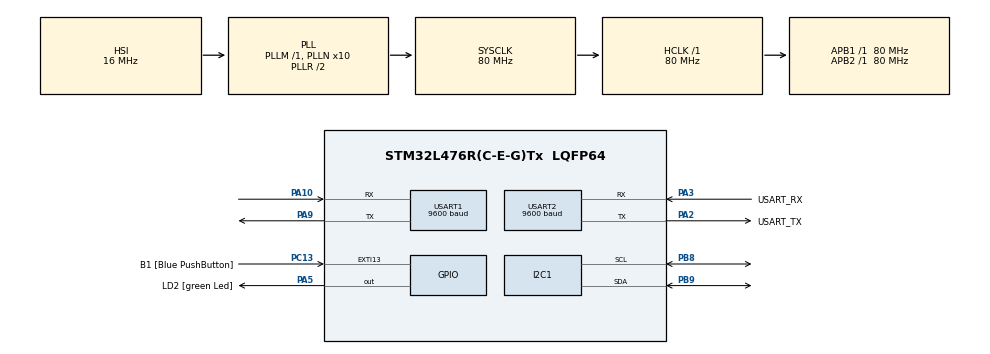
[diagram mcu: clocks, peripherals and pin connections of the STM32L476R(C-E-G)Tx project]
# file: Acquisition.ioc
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I2C1.Timing=0x10D19CE4
Mcu.Family=STM32L4
Mcu.Name=STM32L476R(C-E-G)Tx
Mcu.Package=LQFP64
NVIC.PriorityGroup=NVIC_PRIORITYGROUP_4
PA10.Mode=Asynchronous
PA10.Signal=USART1_RX
PA13\ (JTMS-SWDIO).GPIO_Label=TMS
PA13\ (JTMS-SWDIO).Mode=Serial_Wire
PA13\ (JTMS-SWDIO).Signal=SYS_JTMS-SWDIO
PA14\ (JTCK-SWCLK).GPIO_Label=TCK
PA14\ (JTCK-SWCLK).Mode=Serial_Wire
PA14\ (JTCK-SWCLK).Signal=SYS_JTCK-SWCLK
PA2.GPIO_Label=USART_TX
PA2.GPIO_Mode=GPIO_MODE_AF_PP
PA2.GPIO_PuPd=GPIO_NOPULL
PA2.GPIO_Speed=GPIO_SPEED_FREQ_VERY_HIGH
PA2.Mode=Asynchronous
PA2.Signal=USART2_TX
PA3.GPIO_Label=USART_RX
PA3.GPIO_Mode=GPIO_MODE_AF_PP
PA3.GPIO_PuPd=GPIO_NOPULL
PA3.GPIO_Speed=GPIO_SPEED_FREQ_VERY_HIGH
PA3.Mode=Asynchronous
PA3.Signal=USART2_RX
PA5.GPIO_Label=LD2 [green Led]
PA5.GPIO_ModeDefaultOutputPP=GPIO_MODE_OUTPUT_PP
PA5.GPIO_PuPd=GPIO_NOPULL
PA5.GPIO_Speed=GPIO_SPEED_FREQ_LOW
PA5.Signal=GPIO_Output
PA9.Mode=Asynchronous
PA9.Signal=USART1_TX
PB3\ (JTDO-TRACESWO).GPIO_Label=SWO
PB3\ (JTDO-TRACESWO).Signal=SYS_JTDO-SWO
PB8.Mode=I2C
PB8.Signal=I2C1_SCL
PB9.Mode=I2C
PB9.Signal=I2C1_SDA
PC13.GPIO_Label=B1 [Blue PushButton]
PC13.GPIO_ModeDefaultEXTI=GPIO_MODE_IT_FALLING
PC13.GPIO_PuPd=GPIO_NOPULL
PC13.Signal=GPXTI13
PC14-OSC32_IN\ (PC14).Mode=LSE-External-Oscillator
PC14-OSC32_IN\ (PC14).Signal=RCC_OSC32_IN
PC15-OSC32_OUT\ (PC15).Mode=LSE-External-Oscillator
PC15-OSC32_OUT\ (PC15).Signal=RCC_OSC32_OUT
PH0-OSC_IN\ (PH0).Signal=RCC_OSC_IN
PH1-OSC_OUT\ (PH1).Signal=RCC_OSC_OUT
ProjectManager.HeapSize=0x200
ProjectManager.StackSize=0x400
ProjectManager.TargetToolchain=STM32CubeIDE
RCC.ADCFreq_Value=64000000
RCC.AHBFreq_Value=80000000
RCC.APB1Freq_Value=80000000
RCC.APB1TimFreq_Value=80000000
RCC.APB2Freq_Value=80000000
RCC.APB2TimFreq_Value=80000000
RCC.CortexFreq_Value=80000000
RCC.HCLKFreq_Value=80000000
RCC.HSE_VALUE=8000000
RCC.HSI_VALUE=16000000
RCC.MSI_VALUE=4000000
RCC.PLLN=10
RCC.PLLSourceVirtual=RCC_PLLSOURCE_HSI
RCC.PREFETCH_ENABLE=1
RCC.SYSCLKFreq_VALUE=80000000
RCC.SYSCLKSource=RCC_SYSCLKSOURCE_PLLCLK
RCC.USBFreq_Value=64000000
RCC.VCOOutputFreq_Value=160000000
USART1.BaudRate=9600
USART1.VirtualMode-Asynchronous=VM_ASYNC
USART2.BaudRate=9600
USART2.VirtualMode-Asynchronous=VM_ASYNC
board=NUCLEO-L476RG

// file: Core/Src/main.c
/* USER CODE BEGIN Header */
/**
  ******************************************************************************
  * @file           : main.c
  * @brief          : Main program body
  ******************************************************************************
  * @attention
  *
  * Copyright (c) 2025 STMicroelectronics.
  * All rights reserved.
  *
  * This software is licensed under terms that can be found in the LICENSE file
  * in the root directory of this software component.
  * If no LICENSE file comes with this software, it is provided AS-IS.
  *
  ******************************************************************************
  */
/* USER CODE END Header */

#include "main.h"
#include "i2c.h"
#include "usart.h"
#include "gpio.h"
#include "lcd.h"
#include <string.h>
#include <stdio.h>
#include <stdlib.h>

/* USER CODE BEGIN PV */
// LCD variable
rgb_lcd lcd;

int weightMg;
float weightG;

// LoRa command and response buffers
char loraCmd[64];
char loraResp[256];
char loraMsg[64];
char loraRetMsg[256];

/* USER CODE END PV */

void SystemClock_Config(void);
void displayData(char *message);
void initializePeripherals(void);
void sendLoRaCommand(const char* cmd);
void clearBuffers(void);

/* USER CODE BEGIN PFP */
#define PUTCHAR_PROTOTYPE int __io_putchar(int ch)
/* USER CODE END PFP */

int main(void)
{

  /* MCU Configuration--------------------------------------------------------*/

  /* Reset of all peripherals, Initializes the Flash interface and the Systick. */
  HAL_Init();

  /* Configure the system clock */
  SystemClock_Config();

  /* Initialize all configured peripherals */
  initializePeripherals();

  // Send initial LoRa commands
  sendLoRaCommand("AT\r\n");
  sendLoRaCommand("AT+MODE=TEST\r\n");

  // Set LoRa module to receive mode
  sendLoRaCommand("AT+TEST=RXLRPKT\r\n");

  /* Infinite loop */
  while (1)
  {

    // Wait and retrieve the message
    HAL_UART_Receive(&huart1, (uint8_t*)loraRetMsg, sizeof(loraRetMsg), 1000);
    HAL_UART_Transmit(&huart2, (uint8_t*)loraRetMsg, strlen(loraRetMsg), 1000);

    // Check if the received message contains "+TEST: RX "
    char *start = strstr(loraRetMsg, "+TEST: RX \"");
    if (start != NULL)
    {
        start += 11; // Move past "+TEST: RX \""
        displayData(start);
    }

    // Clear buffers to avoid stale data
    clearBuffers();

  }
}

/**
  * @brief Initialize peripherals and LCD.
  */
void initializePeripherals(void)
{
  MX_GPIO_Init();
  MX_USART2_UART_Init();
  MX_USART1_UART_Init();
  MX_I2C1_Init();

  lcd_init(&hi2c1, &lcd);
  clearlcd();
}

/**
  * @brief Send a command to the LoRa module.
  */
void sendLoRaCommand(const char* cmd)
{
  snprintf(loraCmd, sizeof(loraCmd), "%s", cmd);
  HAL_UART_Transmit(&huart1, (uint8_t*)loraCmd, strlen(loraCmd), 1000);
  HAL_UART_Receive(&huart1, (uint8_t*)loraResp, sizeof(loraResp), 1000);
}

/**
  * @brief Clear the command and response buffers.
  */
void clearBuffers(void)
{
  memset(loraMsg, 0, sizeof(loraMsg));
  memset(loraRetMsg, 0, sizeof(loraRetMsg));
}

/**
  * @brief Display data on the LCD based on the message ID.
  */
void displayData(char *message) {
    char buff[20];

    // Check if the message is from the external temperature and humidity sensor (ID "01")
    if (strncmp(message, "01", 2) == 0) {
        clearlcd();
        lcd_position(&hi2c1, 0, 0);
        lcd_print(&hi2c1, "Temp & Humidity");
        lcd_position(&hi2c1, 0, 1);
        lcd_print(&hi2c1, "Outside");
        HAL_Delay(2000);
        clearlcd();

        // Extract and display temperature
        snprintf(buff, sizeof(buff), "Temp: %c%c.%c%c C", message[2], message[3], message[4], message[5]);
        lcd_position(&hi2c1, 0, 0);
        lcd_print(&hi2c1, buff);
        memset(buff, 0, sizeof(buff));

        // Extract and display humidity
        snprintf(buff, sizeof(buff), "Hum: %c%c.%c%c %%", message[6], message[7], message[8], message[9]);
        lcd_position(&hi2c1, 0, 1);
        lcd_print(&hi2c1, buff);
        memset(buff, 0, sizeof(buff));
    }

    // Check if the message is from the weight sensor (ID "02")
    else if (strncmp(message, "02", 2) == 0) {
        weightMg = atoi(&message[2]); // Convert string to integer (mg)
        weightG = weightMg / 1000.0; // Convert to grams

        clearlcd();
        lcd_position(&hi2c1, 2, 0);
        lcd_print(&hi2c1, "Current Weight");
        lcd_position(&hi2c1, 2, 1);
        lcd_print(&hi2c1, "in Hive");
        HAL_Delay(2000);
        clearlcd();

        lcd_position(&hi2c1, 0, 0);
        lcd_print(&hi2c1, "Hive Weight:");
        snprintf(buff, sizeof(buff), "%.2f g", weightG);
        lcd_position(&hi2c1, 0, 1);
        lcd_print(&hi2c1, buff);
        memset(buff, 0, sizeof(buff));
    }

    // Check for an alternative format of the weight sensor (ID "002")
    else if (strncmp(message, "002", 3) == 0) {
        weightMg = atoi(&message[3]);
        weightG = weightMg / 1000.0;

        clearlcd();
        lcd_position(&hi2c1, 2, 0);
        lcd_print(&hi2c1, "Current Weight");
        lcd_position(&hi2c1, 2, 1);
        lcd_print(&hi2c1, "in Hive");
        HAL_Delay(2000);
        clearlcd();

        lcd_position(&hi2c1, 0, 0);
        lcd_print(&hi2c1, "Hive Weight:");
        snprintf(buff, sizeof(buff), "%.2f g", weightG);
        lcd_position(&hi2c1, 0, 1);
        lcd_print(&hi2c1, buff);
        memset(buff, 0, sizeof(buff));
    }

    // Check if the message is from the internal temperature and humidity sensor (ID "03")
    else if (strncmp(message, "03", 2) == 0) {
        clearlcd();
        lcd_position(&hi2c1, 0, 0);
        lcd_print(&hi2c1, "Temp & Humidity");
        lcd_position(&hi2c1, 0, 1);
        lcd_print(&hi2c1, "Inside");
        HAL_Delay(2000);
        clearlcd();

        // Extract and display temperature
        snprintf(buff, sizeof(buff), "Temp: %c%c.%c C", message[2], message[3], message[4]);
        lcd_position(&hi2c1, 0, 0);
        lcd_print(&hi2c1, buff);
        memset(buff, 0, sizeof(buff));

        // Extract and display humidity
        snprintf(buff, sizeof(buff), "Hum: %c%c.%c %%", message[5], message[6], message[7]);
        lcd_position(&hi2c1, 0, 1);
        lcd_print(&hi2c1, buff);
        memset(buff, 0, sizeof(buff));
    }

    // Check if motion is detected (ID "04")
    else if (strncmp(message, "04", 2) == 0) {
        clearlcd();
        lcd_position(&hi2c1, 2, 0);
        lcd_print(&hi2c1, "PRESENCE");
        lcd_position(&hi2c1, 1, 1);
        lcd_print(&hi2c1, "DETECTED");
    }
}

PUTCHAR_PROTOTYPE // Display printf in terminal
{
  HAL_UART_Transmit(&huart2, (uint8_t *)&ch, 1, 0xFFFF);
  return ch;
}

void SystemClock_Config(void)
{
  RCC_OscInitTypeDef RCC_OscInitStruct = {0};
  RCC_ClkInitTypeDef RCC_ClkInitStruct = {0};

  /** Configure the main internal regulator output voltage */
  if (HAL_PWREx_ControlVoltageScaling(PWR_REGULATOR_VOLTAGE_SCALE1) != HAL_OK)
  {
    Error_Handler();
  }

  /** Initializes the RCC Oscillators according to the specified parameters
  * in the RCC_OscInitTypeDef structure.
  */
  RCC_OscInitStruct.OscillatorType = RCC_OSCILLATORTYPE_HSI;
  RCC_OscInitStruct.HSIState = RCC_HSI_ON;
  RCC_OscInitStruct.HSICalibrationValue = RCC_HSICALIBRATION_DEFAULT;
  RCC_OscInitStruct.PLL.PLLState = RCC_PLL_ON;
  RCC_OscInitStruct.PLL.PLLSource = RCC_PLLSOURCE_HSI;
  RCC_OscInitStruct.PLL.PLLM = 1;
  RCC_OscInitStruct.PLL.PLLN = 10;
  RCC_OscInitStruct.PLL.PLLP = RCC_PLLP_DIV7;
  RCC_OscInitStruct.PLL.PLLQ = RCC_PLLQ_DIV2;
  RCC_OscInitStruct.PLL.PLLR = RCC_PLLR_DIV2;
  if (HAL_RCC_OscConfig(&RCC_OscInitStruct) != HAL_OK)
  {
    Error_Handler();
  }

  /** Initializes the CPU, AHB and APB buses clocks */
  RCC_ClkInitStruct.ClockType = RCC_CLOCKTYPE_HCLK|RCC_CLOCKTYPE_SYSCLK
                              |RCC_CLOCKTYPE_PCLK1|RCC_CLOCKTYPE_PCLK2;
  RCC_ClkInitStruct.SYSCLKSource = RCC_SYSCLKSOURCE_PLLCLK;
  RCC_ClkInitStruct.AHBCLKDivider = RCC_SYSCLK_DIV1;
  RCC_ClkInitStruct.APB1CLKDivider = RCC_HCLK_DIV1;
  RCC_ClkInitStruct.APB2CLKDivider = RCC_HCLK_DIV1;

  if (HAL_RCC_ClockConfig(&RCC_ClkInitStruct, FLASH_LATENCY_4) != HAL_OK)
  {
    Error_Handler();
  }
}

void Error_Handler(void)
{
  __disable_irq();
  while (1)
  {
  }
}
